# M058SAN_v1 register map
File version: 1.0
Registers are 32-bit, read-write, reset 0x0 unless marked. A register's access mark holds for its fields unless they carry their own. Offsets are from the block's base; [hi:lo] are bit positions; {n}, {i} and the like mark numbered series; 'fields as' and 'values as' point back to an identical list.

## PWM — PWM Register Map
Base 0x40040000
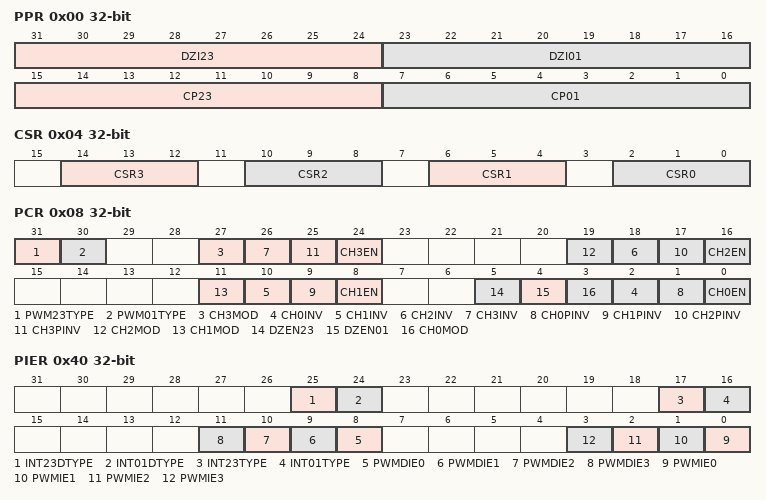
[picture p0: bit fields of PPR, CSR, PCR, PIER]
0x00 PPR — PWM Prescaler Register
  [31:24] DZI23 — Dead zone interval register for pair of channel2 and channel3. These 8 bits determine dead zone length. The unit time of dead zone length is received from corresponding CSR bits.
  [23:16] DZI01 — Dead zone interval register for pair of channel 0 and channel 1. These 8 bits determine dead zone length. The unit time of dead zone length is received from corresponding CSR bits.
  [15:8] CP23 — Clock prescaler 2. Clock input is divided by (CP23 + 1) before it is fed to PWM counter 2 3.
  [7:0] CP01 — Clock prescaler 0. Clock input is divided by (CP01 + 1) before it is fed to PWM counter 0 1.
0x04 CSR — PWM Clock Select Register
  [14:12] CSR3 — Timer 3 Clock Source Selection
  [10:8] CSR2 — Timer 2 Clock Source Selection. Select clock input for PWM timer. (Table is the same as CSR3)
  [6:4] CSR1 — Timer 1 Clock Source Selection. Select clock input for PWM timer. (Table is the same as CSR3)
  [2:0] CSR0 — Timer 0 Clock Source Selection. Select clock input for PWM timer. (Table is the same as CSR3)
0x08 PCR — PWM Control Register
  [31] PWM23TYPE — PWM23 Aligned Type Selection Bit
    0=Edge-aligned type; 1=Center-aligned type
  [30] PWM01TYPE — PWM01 Aligned Type Selection Bit
    0=Edge-aligned type; 1=Center-aligned type
  [27] CH3MOD — PWM-Timer 3 Auto-reload/One-Shot Mode. Note: If there is a transition at this bit, it will cause CNR3 and CMR3 be clear.
    0=One-Shot Mode; 1=Auto-reload Mode
  [8n+2] CH{n}INV (n=0..3) — PWM-Timer {n} Output Inverter ON/OFF
    0=Inverter OFF; 1=Inverter ON
  [8n+1] CH{n}PINV (n=0..3) — PWM-Timer {n} Output Polar Inverse Enable
    0=PWM{n} output polar inverse Disabled; 1=PWM{n} output polar inverse Enabled
  [8n] CH{n}EN (n=0..3) — PWM-Timer {n} Enable/Disable Start Run
    0=Stop corresponding PWM-Timer Running; 1=Enable corresponding PWM-Timer Start Run
  [19] CH2MOD — PWM-Timer 2 Auto-reload/One-Shot Mode. Note: If there is a transition at this bit, it will cause CNR2 and CMR2 be clear.
    0=One-Shot Mode; 1=Auto-reload Mode
  [11] CH1MOD — PWM-Timer 1 Auto-reload/One-Shot Mode. Note: If there is a transition at this bit, it will cause CNR1 and CMR1 be clear.
    0=One-Shot Mode; 1=Auto-load Mode
  [5] DZEN23 — Dead-Zone 2 Generator Enable/Disable. Note: When Dead-Zone Generator is enabled, the pair of PWM2 and PWM3 becomes a complementary pair.
    0=Disable; 1=Enable
  [4] DZEN01 — Dead-Zone 0 Generator Enable/Disable. Note: When Dead-Zone Generator is enabled, the pair of PWM0 and PWM1 becomes a complementary pair.
    0=Disable; 1=Enable
  [3] CH0MOD — PWM-Timer 0 Auto-reload/One-Shot Mode. Note: If there is a transition at this bit, it will cause CNR0 and CMR0 be clear.
    0=One-Shot Mode; 1=Auto-reload Mode
{0xC+0xC*i} CNR{i} (i=0..3) — PWM Counter Register {i}
  [15:0] CNRx — PWM Timer Loaded Value. CNR determines the PWM period. Note: Any write to CNR will take effect in next PWM cycle.
{0x10+0xC*i} CMR{i} (i=0..3) — PWM Comparator Register {i}
  [15:0] CMRx — PWM Comparator Register. CMR determines the PWM duty. Note: Any write to CNR will take effect in next PWM cycle.
{0x14+0xC*i} PDR{i} ro (i=0..3) — PWM Data Register {i}
  [15:0] PDRx — PWM Data Register. User can monitor PDR to know the current value in 16-bit down counter.
0x40 PIER — PWM Interrupt Enable Register
  [25] INT23DTYPE — PWM23 Duty Interrupt Type Selection Bit. Note: Set INT23DTYPE to 1 only work when PWM operating in center aligned type.
    0=PWMDIFn will be set if PWM counter down count and matches CMRn register. PWM will trigger ADC to conversion when PWM counter down count and matches CMRn register if correlate PWM trigger enable bit (PWMnDTEN) is set to 1; 1=PWMDIFn will be set when PWM counter up count and matches CMRn register. PWM will trigger ADC to conversion when PWM counter up count and matches CMRn register if correlate PWM trigger enable bit (PWMnDTEN) is set to 1
  [24] INT01DTYPE — PWM01 Duty Interrupt Type Selection Bit. Note: Set INT01DTYPE to 1 only work when PWM operating in center aligned type.
    values as INT23DTYPE
  [17] INT23TYPE — PWM23 Interrupt Period Type Selection Bit. Note: Set INT23TYPE to 1 only work when PWM operating in center aligned type.
    0=PWMIFn will be set if PWM counter underflow. PWM will trigger ADC to conversion when PWM counter underflow if correlate PWM trigger enable bit (PWMnTEN) is set to 1; 1=PWMIFn will be set if PWM counter matches CNRn register. PWM will trigger ADC to conversion when PWM counter matches CNRn register if correlate PWM trigger enable bit (PWMnTEN) is set to 1
  [16] INT01TYPE — PWM01 Interrupt Period Type Selection Bit. Note: Set INT01TYPE to 1 only work when PWM operating in center aligned type.
    values as INT23TYPE
  [n+8] PWMDIE{n} (n=0..3) — PWM channel {n} Duty Interrupt Enable
    0=Disabled; 1=Enabled
  [n] PWMIE{n} (n=0..3) — PWM channel {n} Period Interrupt Enable
    0=Disable; 1=Enable
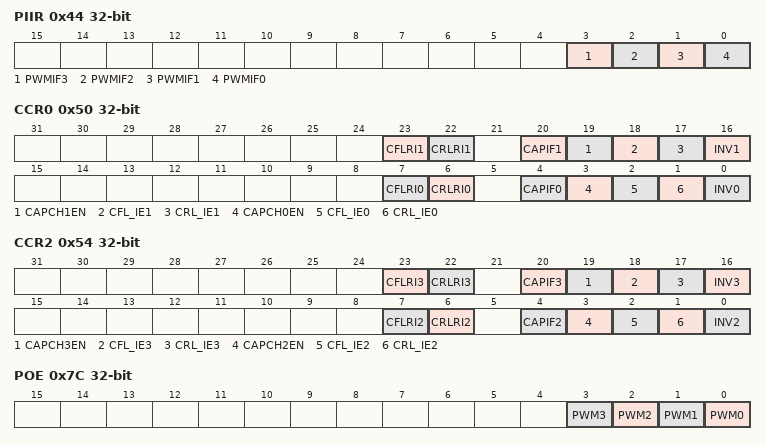
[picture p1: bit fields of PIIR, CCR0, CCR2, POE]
0x44 PIIR — PWM Interrupt Indication Register
  [3] PWMIF3 — PWM channel 3 Period Interrupt Status. This bit is set by hardware when PWM3 counter reaches the requirement of interrupt (depend on INT23TYPE bit of PIER register) if PWM3 interrupt enable bit (PWMIE3) is 1, software can write 1 to clear this bit to zero
  [2] PWMIF2 — PWM channel 2 Period Interrupt Status. This bit is set by hardware when PWM2 counter reaches the requirement of interrupt (depend on INT23TYPE bit of PIER register) if PWM2 interrupt enable bit (PWMIE2) is 1, software can write 1 to clear this bit to zero
  [1] PWMIF1 — PWM channel 1 Period Interrupt Status. This bit is set by hardware when PWM1 counter reaches the requirement of interrupt (depend on INT01TYPE bit of PIER register) if PWM1 interrupt enable bit (PWMIE1) is 1, software can write 1 to clear this bit to zero
  [0] PWMIF0 — PWM channel 0 Period Interrupt Status. This bit is set by hardware when PWM0 counter reaches the requirement of interrupt (depend on INT01TYPE bit of PIER register) if PWM0 interrupt enable bit (PWMIE0) is 1, software can write 1 to clear this bit to zero
0x50 CCR0 — PWM Capture Control Register 0
  [23] CFLRI1 — CFLR1 Latched Indicator Bit. When PWM input channel 1 has a falling transition, CFLR1 was latched with the value of PWM down-counter and this bit is set by hardware. Clear this bit by writing a one to it.
  [22] CRLRI1 — CRLR1 Latched Indicator Bit. When PWM input channel 1 has a rising transition, CRLR1 was latched with the value of PWM down-counter and this bit is set by hardware. Clear this bit by writing a one to it.
  [20] CAPIF1 — Capture1 Interrupt Indication Flag
  [19] CAPCH1EN — Capture PWM Channel 1 transition Enable/Disable. When Enable, Capture latched the PMW-counter and saved to CRLR (Rising latch) and CFLR (Falling latch). When Disable, Capture does not update CRLR and CFLR, and disable PWM channel 1 Interrupt.
    0=Disable capture function on PWM channel 1; 1=Enable capture function on PWM channel 1
  [18] CFL_IE1 — PWM Channel 1 Falling Latch Interrupt Enable. When Enable, if Capture detects PWM channel 1 has falling transition, Capture issues an Interrupt.
    0=Disable falling latch interrupt; 1=Enable falling latch interrupt
  [17] CRL_IE1 — PWM Channel 1 Rising Latch Interrupt Enable. When Enable, if Capture detects PWM channel 1 has rising transition, Capture issues an Interrupt.
    0=Disable rising latch interrupt; 1=Enable rising latch interrupt
  [16] INV1 — PWM Channel 1 Inverter ON/OFF
    0=Inverter OFF; 1=Inverter ON. Reverse the input signal from GPIO before fed to Capture timer
  [7] CFLRI0 — CFLR0 Latched Indicator Bit. When PWM input channel 0 has a falling transition, CFLR0 was latched with the value of PWM down-counter and this bit is set by hardware. Clear this bit by writing a one to it.
  [6] CRLRI0 — CRLR0 Latched Indicator Bit. When PWM input channel 0 has a rising transition, CRLR0 was latched with the value of PWM down-counter and this bit is set by hardware. Clear this bit by writing a one to it.
  [4] CAPIF0 — Capture0 Interrupt Indication Flag
  [3] CAPCH0EN — Capture Channel 0 transition Enable/Disable. When Enable, Capture latched the PWM-counter value and saved to CRLR (Rising latch) and CFLR (Falling latch). When Disable, Capture does not update CRLR and CFLR, and disable PWM channel 0 Interrupt.
    0=Disable capture function on PWM channel 0; 1=Enable capture function on PWM channel 0
  [2] CFL_IE0 — PWM Channel 0 Falling Latch Interrupt Enable ON/OFF. When Enable, if Capture detects PWM channel 0 has falling transition, Capture issues an Interrupt.
    values as CFL_IE1
  [1] CRL_IE0 — PWM Channel 0 Rising Latch Interrupt Enable ON/OFF. When Enable, if Capture detects PWM channel 0 has rising transition, Capture issues an Interrupt.
    values as CRL_IE1
  [0] INV0 — PWM Channel 0 Inverter ON/OFF
    values as INV1
0x54 CCR2 — PWM Capture Control Register 2
  [23] CFLRI3 — CFLR3 Latched Indicator Bit. When PWM input channel 3 has a falling transition, CFLR3 was latched with the value of PWM down-counter and this bit is set by hardware. Write 1 to clear this bit to zero.
  [22] CRLRI3 — CRLR3 Latched Indicator Bit. When PWM input channel 3 has a rising transition, CRLR3 was latched with the value of PWM down-counter and this bit is set by hardware. Write 1 to clear this bit to zero.
  [20] CAPIF3 — Capture3 Interrupt Indication Flag. Write 1 to clear this bit to zero.
  [19] CAPCH3EN — Capture Channel 3 transition Enable/Disable. When Enable, Capture latched the PMW-counter and saved to CRLR (Rising latch) and CFLR (Falling latch). When Disable, Capture does not update CRLR and CFLR, and disable PWM channel 3 Interrupt.
    0=Disable capture function on PWM channel 3; 1=Enable capture function on PWM channel 3
  [18] CFL_IE3 — PWM Channel 3 Falling Latch Interrupt Enable. When Enable, if Capture detects PWM channel 3 has falling transition, Capture issues an Interrupt.
    values as CCR0.CFL_IE1
  [17] CRL_IE3 — PWM Channel 3 Rising Latch Interrupt Enable. When Enable, if Capture detects PWM channel 3 has rising transition, Capture issues an Interrupt.
    values as CCR0.CRL_IE1
  [16] INV3 — PWM Channel 3 Inverter ON/OFF
    values as CCR0.INV1
  [7] CFLRI2 — CFLR2 Latched Indicator Bit. When PWM input channel 2 has a falling transition, CFLR2 was latched with the value of PWM down-counter and this bit is set by hardware. Note: Write 1 to clear this bit to zero.
  [6] CRLRI2 — CRLR2 Latched Indicator Bit. When PWM input channel 2 has a rising transition, CRLR2 was latched with the value of PWM down-counter and this bit is set by hardware. Note: Write 1 to clear this bit to zero.
  [4] CAPIF2 — Capture2 Interrupt Indication Flag. Note: Write 1 to clear this bit to zero.
  [3] CAPCH2EN — Capture Channel 2 transition Enable/Disable. When Enable, Capture latched the PWM-counter value and saved to CRLR (Rising latch) and CFLR (Falling latch). When Disable, Capture does not update CRLR and CFLR, and disable PWM channel 2 Interrupt.
    0=Disable capture function on PWM channel 2; 1=Enable capture function on PWM channel 2
  [2] CFL_IE2 — PWM Channel 2 Falling Latch Interrupt Enable ON/OFF. When Enable, if Capture detects PWM channel 2 has falling transition, Capture issues an Interrupt.
    values as CCR0.CFL_IE1
  [1] CRL_IE2 — PWM Channel 2 Rising Latch Interrupt Enable ON/OFF. When Enable, if Capture detects PWM channel 2 has rising transition, Capture issues an Interrupt.
    values as CCR0.CRL_IE1
  [0] INV2 — PWM Channel 2 Inverter ON/OFF
    values as CCR0.INV1
{0x58+8i} CRLR{i} ro (i=0..3) — PWM Capture Rising Latch Register (Channel {i})
  [15:0] CRLRx — Capture Rising Latch Register. Latch the PWM counter when Channel 0/1/2/3 has rising transition.
{0x5C+8i} CFLR{i} ro (i=0..3) — PWM Capture Falling Latch Register (Channel {i})
  [15:0] CFLRx — Capture Falling Latch Register. Latch the PWM counter when Channel 0/1/2/3 has Falling transition.
0x78 CAPENR — PWM Capture Input 0~3 Enable Register
  [3:0] CAPENR — Capture Input Enable Register. There are four capture inputs from pad. Bit0~Bit3 are used to control each inputs ON or OFF. CAPENR. Bit 3210 for PWM. Bit xxx1 ( Capture channel 0 is from P2.0. Bit xx1x ( Capture channel 1 is from P2.1. Bit x1xx ( Capture channel 2 is from P2.2. Bit 1xxx ( Capture channel 3 is from P2.3
    0=OFF (PWMx multi-function pin input does not affect input capture function.); 1=ON (PWMx multi-function pin input will affect its input capture function.)
0x7C POE — PWM Output Enable Register for channel 0~3
  [n] PWM{n} (n=0..3) — PWM Channel {n} Output Enable Register. Note: The corresponding GPIO pin also must be switched to PWM function
    0=Disable PWM channel {n} output to pin; 1=Enable PWM channel {n} output to pin
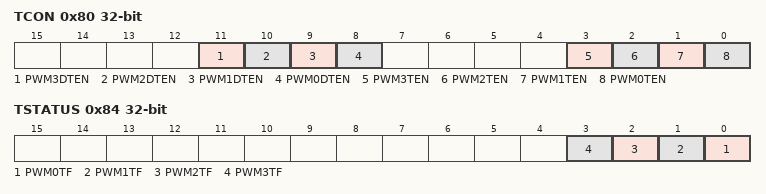
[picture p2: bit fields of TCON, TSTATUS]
0x80 TCON — PWM Trigger Control Register for Channel 0~3
  [11] PWM3DTEN — Channel 3 PWM Duty Trigger ADC Enable Register. As PWM operating at edge-aligned type, enable this bit can make PWM trigger ADC to start conversion when PWM counter down count to match CMR. As PWM operating at center-aligned type, enable this bit can make PWM trigger ADC to start conversion when PWM counter up count or down count to match CMR based on INT23DTYPE setting.
    0=Disable PWM channel 3 trigger ADC function; 1=Enable PWM channel 3 trigger ADC function
  [10] PWM2DTEN — Channel 2 PWM Duty Trigger ADC Enable Register. As PWM operating at edge-aligned type, enable this bit can make PWM trigger ADC to start conversion when PWM counter down count to match CMR. As PWM operating at center-aligned type, enable this bit can make PWM trigger ADC to start conversion when PWM counter up count or down count to match CMR based on INT23DTYPE setting.
    0=Disable PWM channel 2 trigger ADC function; 1=Enable PWM channel 2 trigger ADC function
  [9] PWM1DTEN — Channel 1 PWM Duty Trigger ADC Enable Register. As PWM operating at edge-aligned type, enable this bit can make PWM trigger ADC to start conversion when PWM counter down count to match CMR. As PWM operating at center-aligned type, enable this bit can make PWM trigger ADC to start conversion when PWM counter up count or down count to match CMR based on INT01DTYPE setting.
    0=Disable PWM channel 1 trigger ADC function; 1=Enable PWM channel 1 trigger ADC function
  [8] PWM0DTEN — Channel 0 PWM Duty Trigger ADC Enable Register. As PWM operating at edge-aligned type, enable this bit can make PWM trigger ADC to start conversion when PWM counter down count to match CMR. As PWM operating at center-aligned type, enable this bit can make PWM trigger ADC to start conversion when PWM counter up count or down count to match CMR based on INT01DTYPE setting.
    0=Disable PWM channel 0 trigger ADC function; 1=Enable PWM channel 0 trigger ADC function
  [3] PWM3TEN — Channel 3 PWM Period Trigger ADC Enable Register. As PWM operating at edge-aligned type, enable this bit can make PWM trigger ADC to start conversion when PWM counter down count to underflow. As PWM operating at center-aligned type, enable this bit can make PWM trigger ADC to start conversion when PWM counter up count to (CNR+1) or down count to underflow based on INT23PTYPE setting.
    values as PWM3DTEN
  [2] PWM2TEN — Channel 2 PWM Period Trigger ADC Enable Register. As PWM operating at edge-aligned type, enable this bit can make PWM trigger ADC to start conversion when PWM counter down count to underflow. As PWM operating at center-aligned type, enable this bit can make PWM trigger ADC to start conversion when PWM counter up count to (CNR+1) or down count to underflow based on INT23PTYPE setting.
    values as PWM2DTEN
  [1] PWM1TEN — Channel 1 PWM Period Trigger ADC Enable Register. As PWM operating at edge-aligned type, enable this bit can make PWM trigger ADC to start conversion when PWM counter down count to underflow. As PWM operating at center-aligned type, enable this bit can make PWM trigger ADC to start conversion when PWM counter up count to (CNR+1) or down count to underflow based on INT01PTYPE setting.
    values as PWM1DTEN
  [0] PWM0TEN — Channel 0 PWM Period Trigger ADC Enable Register. As PWM operating at edge-aligned type, enable this bit can make PWM trigger ADC to start conversion when PWM counter down count to underflow. As PWM operating at center-aligned type, enable this bit can make PWM trigger ADC to start conversion when PWM counter up count to (CNR+1) or down count to underflow based on INT01PTYPE setting.
    values as PWM0DTEN
0x84 TSTATUS — PWM Trigger Status Register
  [n] PWM{n}TF (n=0..3) — PWM Channel {n} Trigger ADC Flag. This bit is set to 1 by hardware when PWM{n} trigger ADC condition matched. As this bit is set to 1, ADC will start conversion if ADC triggered source is selected by PWM. Software can write 1 to clear this bit.
0xA0 CAPIC — PWM Capture Interrupt Control Register
  [0] CIENS — PWM Capture interrupt exception Number select. This bit is to enable PWM0-3 capture interrupts have independent interrupt exception number. PWM0-3 capture interrupts are merged into interrupt exception number 22.
    0=Disable PWM0-3 independent capture interrupt exception number; 1=Enable PWM0-3 independent capture interrupt exception number
